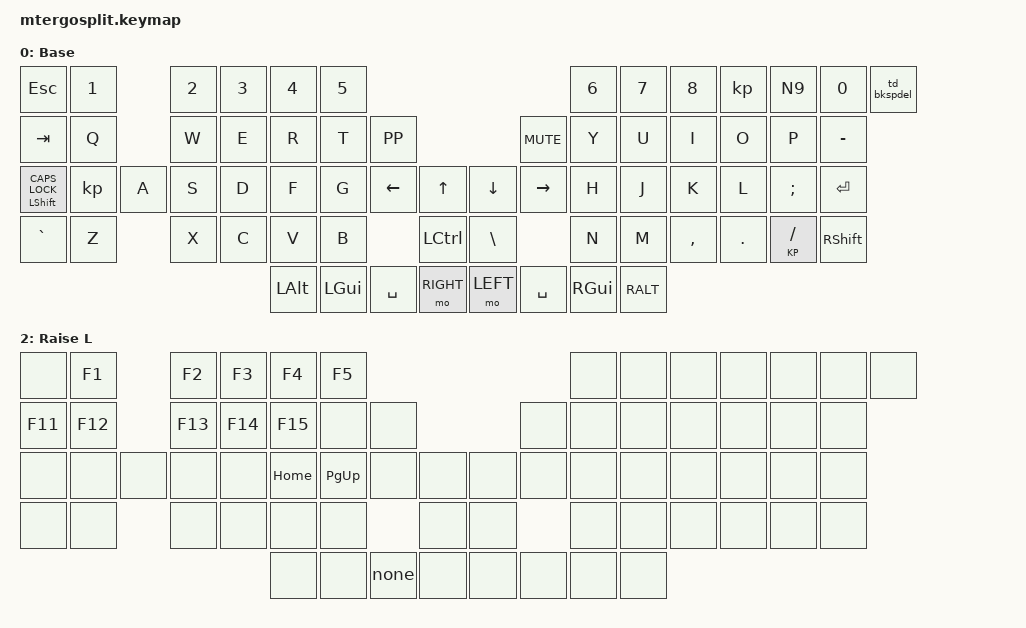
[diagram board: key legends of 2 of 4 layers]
#include <behaviors.dtsi>
#include <dt-bindings/zmk/keys.h>
#include <dt-bindings/zmk/bt.h>

// Assigning layer name to layer number to use in keymap below
#define BASE 0
#define LEFT 1
#define RIGHT 2
#define BTLAYER 3

// Used to set up momentary (hold) vs. toggle (tap) a layer
#define MO_TOG(layer) &mo_tog layer layer 

// Behavior Overrides

&mt {
    tapping-term-ms = <200>; // This is the value already set by default
};

&lt {
    tapping-term-ms = <200>;
    flavor = "hold-preferred";
};

/   {
     behaviors {
       
        // Define a hold-tap behavior named "sh_caps"
        sh_caps: hold_tap_shift_caps {
            compatible = "zmk,behavior-hold-tap";
            // The #binding-cells property is crucial:
            // The tap binding needs 1 parameter (the keycode), and the hold binding needs 1 parameter (the modifier).
            // But ZMK hold-tap definitions use #binding-cells = <2> when defining bindings as <&modifier &key>
            #binding-cells = <2>;
            
            // Adjust these values to your preference to determine tap vs. hold timing
            tapping_term_ms = <200>;
            
            // "tap-preferred" means a quick tap sends the tap function, even if you press another key quickly after
            flavor = "tap-preferred"; 

            // bindings = <hold function>, <tap function>;
            bindings = <&kp>, <&kp>;
        };
     };

    combos {
        compatible = "zmk,combos";
        combo_BT {
            timeout-ms = <50>;
            key-positions = <62 63>;
            bindings = <&mo 3>;
        };
    };
    
    keymap {
        compatible = "zmk,keymap";
        // Keyboard layout  
        
        BASE {
            display-name = "Base";
            bindings = <
            //      Col 0                           Col 1           Col 2      Col 3       Col 4       Col 5       Col 6            Col 7           Col 8            Col 9           Col 10          Col 11      Col 12          Col 13      Col 14           Col 15

                    &kp ESC                         &kp N1          &kp N2      &kp N3      &kp N4      &kp N5                                                                      &kp N6          &kp N7      &kp N8          kp N9       &kp N0          &td_bkspdel            
                    &kp TAB                         &kp Q           &kp W       &kp E       &kp R       &kp T       &kp K_PP                                        &kp K_MUTE      &kp Y           &kp U       &kp I           &kp O       &kp P           &kp MINUS        
                    &sh_caps LSHIFT CAPS_LOCK       kp A            &kp S       &kp D       &kp F       &kp G       &kp LEFT        &kp UP          &kp DOWN        &kp RIGHT       &kp H           &kp J       &kp K           &kp L       &kp SEMI        &kp RETURN   
                    &kp GRAVE                       &kp Z           &kp X       &kp C       &kp V       &kp B                       &kp LCTRL       &kp BACKSLASH                   &kp N           &kp M       &kp COMMA       &kp DOT     &KP SLASH       &kp RSHIFT
                                                                                            &kp LALT    &kp LGUI    &kp SPACE       &mo RIGHT       &mo LEFT        &kp SPACE       &kp RGUI        &RALT
           
            >;
        };

        RIGHT {
            display-name = "Raise R";
            bindings = <
            //  Col 0   Col 1       Col 2       Col 3       Col 4       Col 5       Col 6       Col 7           Col 8       Col 9       Col 10      Col 11      Col 12      Col 13      Col 14          Col 15  
                &none   &none       &none       &none       &none       &none                                                           &kp F6      &kp F7      &kp F8      &kp F9      &kp F10         &none
                &none   &none       &none       &none       &none       &none       &none                                   &none       &none       &none       &none       &none       &none           &kp EQUAL
                &none   &none       &none       &none       &none       &none       &none       &none       &kp PG_DN       &kp END     &none       &none       &none       &none       &td_SQT_DQT     &none 
                                                            &none       &none       &none       &none       &none           &none       &none       &none       
            >;
        };

        LEFT {
            display-name = "Raise L";
            bindings = <
            //  Col 0   Col 1       Col 2       Col 3       Col 4       Col 5       Col 6       Col 7           Col 8       Col 9       Col 10      Col 11      Col 12      Col 13      Col 14      Col 15  
                &none   &kp F1      &kp F2      &kp F3      &kp F4      &kp F5                                                          &none       &none       &none       &none       &none       &none
                &none   &kp F11     &kp F12     &kp F13     &kp F14     &kp F15     &none                                   &none       &none       &none       &none       &none       &none       &none
                &none   &none       &none       &none       &none       &none       &kp HOME    &kp PG_UP       &none       &none       &none       &none       &none       &none       &none       &none
                &none   &none       &none       &none       &none       &none       &none       &none           &none       &none       &none       &none       &none       &none       &none       &none
                                                            &none       &none       none        &none           &none       &none       &none       &none           
            >;
            >;
        };

        BTLAYER {
            display-name = "Bluetooth";
            bindings =<
            //  Col 0   Col 1           Col 2               Col 3           Col 4      Col 5        Col 6       Col 7   Col 8   Col 9   Col 10  Col 11  Col 12  Col 13  Col 14  Col 15
                &none   &bt BT_SEL 0    &bt BT_SEL 1        &bt BT_SEL 2    &none      &none                                            &none   &none   &none   &none   &none   &none
                &none   &bt BT_CLR      &bt BT_CLR_ALL      &none           &none      &none        &none                       &none   &none   &none   &none   &none   &none   &none
                &none   &none           &none               &none           &none      &none        &none       &none   &none   &none   &none   &none   &none   &none   &none   &none
                &none   &none           &none               &none           &none      &sys_reset               &none   &none           &none   &none   &none   &none   &none   &none 
                                                                            &none      &none        &none       &none   &none   &none   &none   &none           
            >;
        };
    };
};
